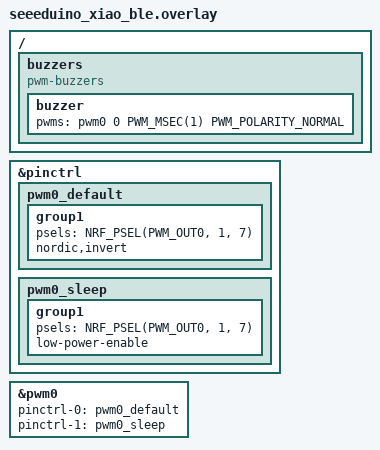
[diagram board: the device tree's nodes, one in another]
/*
 * Copyright (c) 2025 The ZMK Contributors
 *
 * SPDX-License-Identifier: MIT
 */

// Buzzer configuration for Xiao BLE plus
// RP2040 does not have enough pins for buzzer

/ {
    buzzers {
        compatible = "pwm-buzzers";
        status = "okay";
        buzzer: buzzer {
            pwms = <&pwm0 0 PWM_MSEC(1) PWM_POLARITY_NORMAL>;
        };
    };
};

&pinctrl {
    pwm0_default: pwm0_default {
        group1 {
            psels = <NRF_PSEL(PWM_OUT0, 1, 7)>;
            nordic,invert;
        };
    };

    pwm0_sleep: pwm0_sleep {
        group1 {
            psels = <NRF_PSEL(PWM_OUT0, 1, 7)>;
            low-power-enable;
        };
    };
};

&pwm0 {
    status = "okay";
    pinctrl-0 = <&pwm0_default>;
    pinctrl-1 = <&pwm0_sleep>;
    pinctrl-names = "default", "sleep";
};
